AUTOSAR XML (schema 00048)
package /MICROSAR/ComM_swc
  mode declaration group ComMMode: initial-mode=COMM_NO_COMMUNICATION
    mode COMM_NO_COMMUNICATION
    mode COMM_SILENT_COMMUNICATION
    mode COMM_FULL_COMMUNICATION
  data type mapping set ComMMode_DataTypeMappingSet: mode-request-type-map{implementation-data-type=ComM_ModeType, mode-group=ComMMode}  # Data Mapping for the Mode Declaration Group ComMMode.
package /MICROSAR/ComM_swc/DataTypes
  4 x impl type, all with category=TYPE_REFERENCE:
    ComM_ModeType: compu {0=COMM_NO_COMMUNICATION, 1=COMM_SILENT_COMMUNICATION, 2=COMM_FULL_COMMUNICATION}, range raw 0..3, implementation-data-type=uint8
    ComM_InhibitionStatusType: range raw 0..255, implementation-data-type=uint8
    ComM_UserHandleType: range raw 0..65535, implementation-data-type=uint16
    NetworkHandleType: range raw 0..255, implementation-data-type=uint8, type-emitter=ComM
package /MICROSAR/ComM_swc/Interfaces
  4 x client server interface, all with is-service=true, service-kind=COM-MANAGER:
    ComM_UserRequest
      5 x operation:
        RequestComMode: possible-error=[ComM_UserRequest/E_NOT_OK, E_MODE_LIMITATION]
          arg ComMode: type=ComM_ModeType, direction=IN
        GetCurrentComMode: possible-error=ComM_UserRequest/E_NOT_OK
          arg ComMode: type=ComM_ModeType, direction=OUT
        GetMaxComMode: possible-error=ComM_UserRequest/E_NOT_OK
          arg ComMode: type=ComM_ModeType, direction=OUT
        GetRequestedComMode: possible-error=ComM_UserRequest/E_NOT_OK
          arg ComMode: type=ComM_ModeType, direction=OUT
        GetCurrentPNCComMode: possible-error=[ComM_UserRequest/E_NOT_OK, E_MULTIPLE_PNC_ASSIGNED, E_NO_PNC_ASSIGNED]
          arg ComMode: type=ComM_ModeType, direction=OUT
      4 x error:
        E_NOT_OK: error-code=1
        E_MODE_LIMITATION: error-code=2
        E_MULTIPLE_PNC_ASSIGNED: error-code=3
        E_NO_PNC_ASSIGNED: error-code=4
    ComM_ECUModeLimitation
      4 x operation, all with possible-error=ComM_ECUModeLimitation/E_NOT_OK:
        LimitECUToNoComMode
          arg Status: type=boolean, direction=IN
        ReadInhibitCounter
          arg CounterValue: type=uint16, direction=OUT
        ResetInhibitCounter
        SetECUGroupClassification
          arg Status: type=ComM_InhibitionStatusType, direction=IN
      error E_NOT_OK: error-code=1
    ComM_ChannelWakeUp
      operation PreventWakeUp: possible-error=ComM_ChannelWakeUp/E_NOT_OK
        arg Status: type=boolean, direction=IN
      operation GetInhibitionStatus: possible-error=ComM_ChannelWakeUp/E_NOT_OK
        arg Status: type=ComM_InhibitionStatusType, direction=OUT
      error E_NOT_OK: error-code=1
    ComM_ChannelLimitation
      operation LimitChannelToNoComMode: possible-error=ComM_ChannelLimitation/E_NOT_OK
        arg Status: type=boolean, direction=IN
      operation GetInhibitionStatus: possible-error=ComM_ChannelLimitation/E_NOT_OK
        arg Status: type=ComM_InhibitionStatusType, direction=OUT
      error E_NOT_OK: error-code=1
  mode switch interface ComM_CurrentMode: is-service=true, service-kind=COM-MANAGER
    mode group currentMode: type=ComMMode
package /MICROSAR/ComM_swc/ComponentTypes
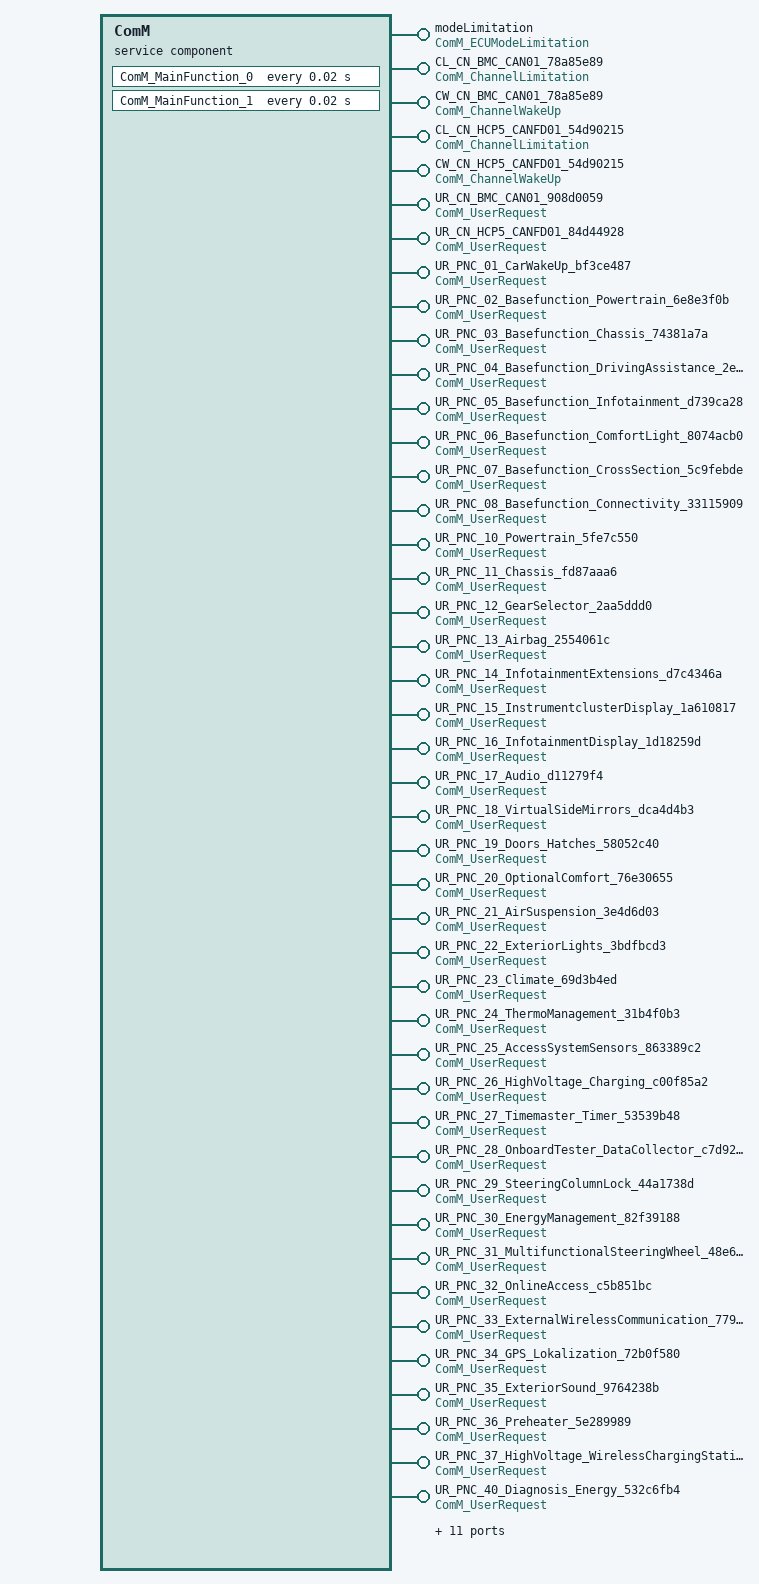
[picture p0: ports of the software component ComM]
  service sw component type ComM: category=SERVICE_COMPONENT
    55 x provide port:
      modeLimitation: provided-interface=ComM_ECUModeLimitation
      CL_CN_BMC_CAN01_78a85e89: provided-interface=ComM_ChannelLimitation
      CW_CN_BMC_CAN01_78a85e89: provided-interface=ComM_ChannelWakeUp
      CL_CN_HCP5_CANFD01_54d90215: provided-interface=ComM_ChannelLimitation
      CW_CN_HCP5_CANFD01_54d90215: provided-interface=ComM_ChannelWakeUp
      UR_CN_BMC_CAN01_908d0059: provided-interface=ComM_UserRequest
      UR_CN_HCP5_CANFD01_84d44928: provided-interface=ComM_UserRequest
      UR_PNC_01_CarWakeUp_bf3ce487: provided-interface=ComM_UserRequest
      UR_PNC_02_Basefunction_Powertrain_6e8e3f0b: provided-interface=ComM_UserRequest
      UR_PNC_03_Basefunction_Chassis_74381a7a: provided-interface=ComM_UserRequest
      UR_PNC_04_Basefunction_DrivingAssistance_2e755e80: provided-interface=ComM_UserRequest
      UR_PNC_05_Basefunction_Infotainment_d739ca28: provided-interface=ComM_UserRequest
      UR_PNC_06_Basefunction_ComfortLight_8074acb0: provided-interface=ComM_UserRequest
      UR_PNC_07_Basefunction_CrossSection_5c9febde: provided-interface=ComM_UserRequest
      UR_PNC_08_Basefunction_Connectivity_33115909: provided-interface=ComM_UserRequest
      UR_PNC_10_Powertrain_5fe7c550: provided-interface=ComM_UserRequest
      UR_PNC_11_Chassis_fd87aaa6: provided-interface=ComM_UserRequest
      UR_PNC_12_GearSelector_2aa5ddd0: provided-interface=ComM_UserRequest
      UR_PNC_13_Airbag_2554061c: provided-interface=ComM_UserRequest
      UR_PNC_14_InfotainmentExtensions_d7c4346a: provided-interface=ComM_UserRequest
      UR_PNC_15_InstrumentclusterDisplay_1a610817: provided-interface=ComM_UserRequest
      UR_PNC_16_InfotainmentDisplay_1d18259d: provided-interface=ComM_UserRequest
      UR_PNC_17_Audio_d11279f4: provided-interface=ComM_UserRequest
      UR_PNC_18_VirtualSideMirrors_dca4d4b3: provided-interface=ComM_UserRequest
      UR_PNC_19_Doors_Hatches_58052c40: provided-interface=ComM_UserRequest
      UR_PNC_20_OptionalComfort_76e30655: provided-interface=ComM_UserRequest
      UR_PNC_21_AirSuspension_3e4d6d03: provided-interface=ComM_UserRequest
      UR_PNC_22_ExteriorLights_3bdfbcd3: provided-interface=ComM_UserRequest
      UR_PNC_23_Climate_69d3b4ed: provided-interface=ComM_UserRequest
      UR_PNC_24_ThermoManagement_31b4f0b3: provided-interface=ComM_UserRequest
      UR_PNC_25_AccessSystemSensors_863389c2: provided-interface=ComM_UserRequest
      UR_PNC_26_HighVoltage_Charging_c00f85a2: provided-interface=ComM_UserRequest
      UR_PNC_27_Timemaster_Timer_53539b48: provided-interface=ComM_UserRequest
      UR_PNC_28_OnboardTester_DataCollector_c7d92e04: provided-interface=ComM_UserRequest
      UR_PNC_29_SteeringColumnLock_44a1738d: provided-interface=ComM_UserRequest
      UR_PNC_30_EnergyManagement_82f39188: provided-interface=ComM_UserRequest
      UR_PNC_31_MultifunctionalSteeringWheel_48e6d667: provided-interface=ComM_UserRequest
      UR_PNC_32_OnlineAccess_c5b851bc: provided-interface=ComM_UserRequest
      UR_PNC_33_ExternalWirelessCommunication_779a8708: provided-interface=ComM_UserRequest
      UR_PNC_34_GPS_Lokalization_72b0f580: provided-interface=ComM_UserRequest
      UR_PNC_35_ExteriorSound_9764238b: provided-interface=ComM_UserRequest
      UR_PNC_36_Preheater_5e289989: provided-interface=ComM_UserRequest
      UR_PNC_37_HighVoltage_WirelessChargingStation_f111c76f: provided-interface=ComM_UserRequest
      UR_PNC_40_Diagnosis_Energy_532c6fb4: provided-interface=ComM_UserRequest
      UR_PNC_41_Diagnosis_Powertrain_0ac6ac8b: provided-interface=ComM_UserRequest
      UR_PNC_42_Diagnosis_FlexRay_f6dcf44d: provided-interface=ComM_UserRequest
      UR_PNC_43_Diagnosis_DrivingAssistance_84f09039: provided-interface=ComM_UserRequest
      UR_PNC_44_Diagnosis_Infotainment_3909218a: provided-interface=ComM_UserRequest
      UR_PNC_45_Diagnosis_Comfort_7eea372a: provided-interface=ComM_UserRequest
      UR_PNC_46_Diagnosis_Light_5140c135: provided-interface=ComM_UserRequest
      UR_PNC_47_Diagnosis_ComfortLINs_70cf0372: provided-interface=ComM_UserRequest
      UR_PNC_48_Diagnosis_ClimateTmeLINs_b4c40b49: provided-interface=ComM_UserRequest
      UR_PNC_53_Lock_Unlock_bfb0b2ca: provided-interface=ComM_UserRequest
      UR_PNC_55_Dimming_4909a14c: provided-interface=ComM_UserRequest
      UR_PNC_56_Charging_Status_cad5dfb4: provided-interface=ComM_UserRequest
    behavior ComMInternalBehavior: data-type-mapping=ComMMode_DataTypeMappingSet, handle-termination-and-restart=NO-SUPPORT, included-data-type-set=data-type=[ComM_ModeType, ComM_InhibitionStatusType, ComM_UserHandleType, NetworkHandleType]
      timing event Timer_ComM_MainFunction_0: start-on-event=ComM_MainFunction_0, period=0.02
      timing event Timer_ComM_MainFunction_1: start-on-event=ComM_MainFunction_1, period=0.02
      262 x operation invoked event:
        OpEventLimitECUToNoComMode_LimitECUToNoComMode_modeLimitation: start-on-event=LimitECUToNoComMode, operation=modeLimitation.LimitECUToNoComMode
        OpEventReadInhibitCounter_ReadInhibitCounter_modeLimitation: start-on-event=ReadInhibitCounter, operation=modeLimitation.ReadInhibitCounter
        OpEventResetInhibitCounter_ResetInhibitCounter_modeLimitation: start-on-event=ResetInhibitCounter, operation=modeLimitation.ResetInhibitCounter
        OpEventSetECUGroupClassification_SetECUGroupClassification_modeLimitation: start-on-event=SetECUGroupClassification, operation=modeLimitation.SetECUGroupClassification
        OpEventGetInhibitionStatus_GetInhibitionStatus_CL_CN_BMC_CAN01_78a85e89: start-on-event=GetInhibitionStatus, operation=CL_CN_BMC_CAN01_78a85e89.GetInhibitionStatus
        OpEventGetInhibitionStatus_GetInhibitionStatus_CW_CN_BMC_CAN01_78a85e89: start-on-event=GetInhibitionStatus, operation=CW_CN_BMC_CAN01_78a85e89.GetInhibitionStatus
        OpEventGetInhibitionStatus_GetInhibitionStatus_CL_CN_HCP5_CANFD01_54d90215: start-on-event=GetInhibitionStatus, operation=CL_CN_HCP5_CANFD01_54d90215.GetInhibitionStatus
        OpEventGetInhibitionStatus_GetInhibitionStatus_CW_CN_HCP5_CANFD01_54d90215: start-on-event=GetInhibitionStatus, operation=CW_CN_HCP5_CANFD01_54d90215.GetInhibitionStatus
        OpEventLimitChannelToNoComMode_LimitChannelToNoComMode_CL_CN_BMC_CAN01_78a85e89: start-on-event=LimitChannelToNoComMode, operation=CL_CN_BMC_CAN01_78a85e89.LimitChannelToNoComMode
        OpEventLimitChannelToNoComMode_LimitChannelToNoComMode_CL_CN_HCP5_CANFD01_54d90215: start-on-event=LimitChannelToNoComMode, operation=CL_CN_HCP5_CANFD01_54d90215.LimitChannelToNoComMode
        OpEventPreventWakeUp_PreventWakeUp_CW_CN_BMC_CAN01_78a85e89: start-on-event=PreventWakeUp, operation=CW_CN_BMC_CAN01_78a85e89.PreventWakeUp
        OpEventPreventWakeUp_PreventWakeUp_CW_CN_HCP5_CANFD01_54d90215: start-on-event=PreventWakeUp, operation=CW_CN_HCP5_CANFD01_54d90215.PreventWakeUp
        OpEventRequestComMode_RequestComMode_UR_CN_BMC_CAN01_908d0059: start-on-event=RequestComMode, operation=UR_CN_BMC_CAN01_908d0059.RequestComMode
        OpEventRequestComMode_RequestComMode_UR_CN_HCP5_CANFD01_84d44928: start-on-event=RequestComMode, operation=UR_CN_HCP5_CANFD01_84d44928.RequestComMode
        OpEventRequestComMode_RequestComMode_UR_PNC_01_CarWakeUp_bf3ce487: start-on-event=RequestComMode, operation=UR_PNC_01_CarWakeUp_bf3ce487.RequestComMode
        OpEventRequestComMode_RequestComMode_UR_PNC_02_Basefunction_Powertrain_6e8e3f0b: start-on-event=RequestComMode, operation=UR_PNC_02_Basefunction_Powertrain_6e8e3f0b.RequestComMode
        OpEventRequestComMode_RequestComMode_UR_PNC_03_Basefunction_Chassis_74381a7a: start-on-event=RequestComMode, operation=UR_PNC_03_Basefunction_Chassis_74381a7a.RequestComMode
        OpEventRequestComMode_RequestComMode_UR_PNC_04_Basefunction_DrivingAssistance_2e755e80: start-on-event=RequestComMode, operation=UR_PNC_04_Basefunction_DrivingAssistance_2e755e80.RequestComMode
        OpEventRequestComMode_RequestComMode_UR_PNC_05_Basefunction_Infotainment_d739ca28: start-on-event=RequestComMode, operation=UR_PNC_05_Basefunction_Infotainment_d739ca28.RequestComMode
        OpEventRequestComMode_RequestComMode_UR_PNC_06_Basefunction_ComfortLight_8074acb0: start-on-event=RequestComMode, operation=UR_PNC_06_Basefunction_ComfortLight_8074acb0.RequestComMode
        OpEventRequestComMode_RequestComMode_UR_PNC_07_Basefunction_CrossSection_5c9febde: start-on-event=RequestComMode, operation=UR_PNC_07_Basefunction_CrossSection_5c9febde.RequestComMode
        OpEventRequestComMode_RequestComMode_UR_PNC_08_Basefunction_Connectivity_33115909: start-on-event=RequestComMode, operation=UR_PNC_08_Basefunction_Connectivity_33115909.RequestComMode
        OpEventRequestComMode_RequestComMode_UR_PNC_10_Powertrain_5fe7c550: start-on-event=RequestComMode, operation=UR_PNC_10_Powertrain_5fe7c550.RequestComMode
        OpEventRequestComMode_RequestComMode_UR_PNC_11_Chassis_fd87aaa6: start-on-event=RequestComMode, operation=UR_PNC_11_Chassis_fd87aaa6.RequestComMode
        OpEventRequestComMode_RequestComMode_UR_PNC_12_GearSelector_2aa5ddd0: start-on-event=RequestComMode, operation=UR_PNC_12_GearSelector_2aa5ddd0.RequestComMode
        OpEventRequestComMode_RequestComMode_UR_PNC_13_Airbag_2554061c: start-on-event=RequestComMode, operation=UR_PNC_13_Airbag_2554061c.RequestComMode
        OpEventRequestComMode_RequestComMode_UR_PNC_14_InfotainmentExtensions_d7c4346a: start-on-event=RequestComMode, operation=UR_PNC_14_InfotainmentExtensions_d7c4346a.RequestComMode
        OpEventRequestComMode_RequestComMode_UR_PNC_15_InstrumentclusterDisplay_1a610817: start-on-event=RequestComMode, operation=UR_PNC_15_InstrumentclusterDisplay_1a610817.RequestComMode
        OpEventRequestComMode_RequestComMode_UR_PNC_16_InfotainmentDisplay_1d18259d: start-on-event=RequestComMode, operation=UR_PNC_16_InfotainmentDisplay_1d18259d.RequestComMode
        OpEventRequestComMode_RequestComMode_UR_PNC_17_Audio_d11279f4: start-on-event=RequestComMode, operation=UR_PNC_17_Audio_d11279f4.RequestComMode
        OpEventRequestComMode_RequestComMode_UR_PNC_18_VirtualSideMirrors_dca4d4b3: start-on-event=RequestComMode, operation=UR_PNC_18_VirtualSideMirrors_dca4d4b3.RequestComMode
        OpEventRequestComMode_RequestComMode_UR_PNC_19_Doors_Hatches_58052c40: start-on-event=RequestComMode, operation=UR_PNC_19_Doors_Hatches_58052c40.RequestComMode
        OpEventRequestComMode_RequestComMode_UR_PNC_20_OptionalComfort_76e30655: start-on-event=RequestComMode, operation=UR_PNC_20_OptionalComfort_76e30655.RequestComMode
        OpEventRequestComMode_RequestComMode_UR_PNC_21_AirSuspension_3e4d6d03: start-on-event=RequestComMode, operation=UR_PNC_21_AirSuspension_3e4d6d03.RequestComMode
        OpEventRequestComMode_RequestComMode_UR_PNC_22_ExteriorLights_3bdfbcd3: start-on-event=RequestComMode, operation=UR_PNC_22_ExteriorLights_3bdfbcd3.RequestComMode
        OpEventRequestComMode_RequestComMode_UR_PNC_23_Climate_69d3b4ed: start-on-event=RequestComMode, operation=UR_PNC_23_Climate_69d3b4ed.RequestComMode
        OpEventRequestComMode_RequestComMode_UR_PNC_24_ThermoManagement_31b4f0b3: start-on-event=RequestComMode, operation=UR_PNC_24_ThermoManagement_31b4f0b3.RequestComMode
        OpEventRequestComMode_RequestComMode_UR_PNC_25_AccessSystemSensors_863389c2: start-on-event=RequestComMode, operation=UR_PNC_25_AccessSystemSensors_863389c2.RequestComMode
        OpEventRequestComMode_RequestComMode_UR_PNC_26_HighVoltage_Charging_c00f85a2: start-on-event=RequestComMode, operation=UR_PNC_26_HighVoltage_Charging_c00f85a2.RequestComMode
        OpEventRequestComMode_RequestComMode_UR_PNC_27_Timemaster_Timer_53539b48: start-on-event=RequestComMode, operation=UR_PNC_27_Timemaster_Timer_53539b48.RequestComMode
        OpEventRequestComMode_RequestComMode_UR_PNC_28_OnboardTester_DataCollector_c7d92e04: start-on-event=RequestComMode, operation=UR_PNC_28_OnboardTester_DataCollector_c7d92e04.RequestComMode
        OpEventRequestComMode_RequestComMode_UR_PNC_29_SteeringColumnLock_44a1738d: start-on-event=RequestComMode, operation=UR_PNC_29_SteeringColumnLock_44a1738d.RequestComMode
        OpEventRequestComMode_RequestComMode_UR_PNC_30_EnergyManagement_82f39188: start-on-event=RequestComMode, operation=UR_PNC_30_EnergyManagement_82f39188.RequestComMode
        OpEventRequestComMode_RequestComMode_UR_PNC_31_MultifunctionalSteeringWheel_48e6d667: start-on-event=RequestComMode, operation=UR_PNC_31_MultifunctionalSteeringWheel_48e6d667.RequestComMode
        OpEventRequestComMode_RequestComMode_UR_PNC_32_OnlineAccess_c5b851bc: start-on-event=RequestComMode, operation=UR_PNC_32_OnlineAccess_c5b851bc.RequestComMode
        OpEventRequestComMode_RequestComMode_UR_PNC_33_ExternalWirelessCommunication_779a8708: start-on-event=RequestComMode, operation=UR_PNC_33_ExternalWirelessCommunication_779a8708.RequestComMode
        OpEventRequestComMode_RequestComMode_UR_PNC_34_GPS_Lokalization_72b0f580: start-on-event=RequestComMode, operation=UR_PNC_34_GPS_Lokalization_72b0f580.RequestComMode
        OpEventRequestComMode_RequestComMode_UR_PNC_35_ExteriorSound_9764238b: start-on-event=RequestComMode, operation=UR_PNC_35_ExteriorSound_9764238b.RequestComMode
        OpEventRequestComMode_RequestComMode_UR_PNC_36_Preheater_5e289989: start-on-event=RequestComMode, operation=UR_PNC_36_Preheater_5e289989.RequestComMode
        OpEventRequestComMode_RequestComMode_UR_PNC_37_HighVoltage_WirelessChargingStation_f111c76f: start-on-event=RequestComMode, operation=UR_PNC_37_HighVoltage_WirelessChargingStation_f111c76f.RequestComMode
        OpEventRequestComMode_RequestComMode_UR_PNC_40_Diagnosis_Energy_532c6fb4: start-on-event=RequestComMode, operation=UR_PNC_40_Diagnosis_Energy_532c6fb4.RequestComMode
        OpEventRequestComMode_RequestComMode_UR_PNC_41_Diagnosis_Powertrain_0ac6ac8b: start-on-event=RequestComMode, operation=UR_PNC_41_Diagnosis_Powertrain_0ac6ac8b.RequestComMode
        OpEventRequestComMode_RequestComMode_UR_PNC_42_Diagnosis_FlexRay_f6dcf44d: start-on-event=RequestComMode, operation=UR_PNC_42_Diagnosis_FlexRay_f6dcf44d.RequestComMode
        OpEventRequestComMode_RequestComMode_UR_PNC_43_Diagnosis_DrivingAssistance_84f09039: start-on-event=RequestComMode, operation=UR_PNC_43_Diagnosis_DrivingAssistance_84f09039.RequestComMode
        OpEventRequestComMode_RequestComMode_UR_PNC_44_Diagnosis_Infotainment_3909218a: start-on-event=RequestComMode, operation=UR_PNC_44_Diagnosis_Infotainment_3909218a.RequestComMode
        OpEventRequestComMode_RequestComMode_UR_PNC_45_Diagnosis_Comfort_7eea372a: start-on-event=RequestComMode, operation=UR_PNC_45_Diagnosis_Comfort_7eea372a.RequestComMode
        OpEventRequestComMode_RequestComMode_UR_PNC_46_Diagnosis_Light_5140c135: start-on-event=RequestComMode, operation=UR_PNC_46_Diagnosis_Light_5140c135.RequestComMode
        OpEventRequestComMode_RequestComMode_UR_PNC_47_Diagnosis_ComfortLINs_70cf0372: start-on-event=RequestComMode, operation=UR_PNC_47_Diagnosis_ComfortLINs_70cf0372.RequestComMode
        OpEventRequestComMode_RequestComMode_UR_PNC_48_Diagnosis_ClimateTmeLINs_b4c40b49: start-on-event=RequestComMode, operation=UR_PNC_48_Diagnosis_ClimateTmeLINs_b4c40b49.RequestComMode
        OpEventRequestComMode_RequestComMode_UR_PNC_53_Lock_Unlock_bfb0b2ca: start-on-event=RequestComMode, operation=UR_PNC_53_Lock_Unlock_bfb0b2ca.RequestComMode
        OpEventRequestComMode_RequestComMode_UR_PNC_55_Dimming_4909a14c: start-on-event=RequestComMode, operation=UR_PNC_55_Dimming_4909a14c.RequestComMode
        OpEventRequestComMode_RequestComMode_UR_PNC_56_Charging_Status_cad5dfb4: start-on-event=RequestComMode, operation=UR_PNC_56_Charging_Status_cad5dfb4.RequestComMode
        OpEventGetCurrentComMode_GetCurrentComMode_UR_CN_BMC_CAN01_908d0059: start-on-event=GetCurrentComMode, operation=UR_CN_BMC_CAN01_908d0059.GetCurrentComMode
        OpEventGetCurrentComMode_GetCurrentComMode_UR_CN_HCP5_CANFD01_84d44928: start-on-event=GetCurrentComMode, operation=UR_CN_HCP5_CANFD01_84d44928.GetCurrentComMode
        OpEventGetCurrentComMode_GetCurrentComMode_UR_PNC_01_CarWakeUp_bf3ce487: start-on-event=GetCurrentComMode, operation=UR_PNC_01_CarWakeUp_bf3ce487.GetCurrentComMode
        OpEventGetCurrentComMode_GetCurrentComMode_UR_PNC_02_Basefunction_Powertrain_6e8e3f0b: start-on-event=GetCurrentComMode, operation=UR_PNC_02_Basefunction_Powertrain_6e8e3f0b.GetCurrentComMode
        OpEventGetCurrentComMode_GetCurrentComMode_UR_PNC_03_Basefunction_Chassis_74381a7a: start-on-event=GetCurrentComMode, operation=UR_PNC_03_Basefunction_Chassis_74381a7a.GetCurrentComMode
        OpEventGetCurrentComMode_GetCurrentComMode_UR_PNC_04_Basefunction_DrivingAssistance_2e755e80: start-on-event=GetCurrentComMode, operation=UR_PNC_04_Basefunction_DrivingAssistance_2e755e80.GetCurrentComMode
        OpEventGetCurrentComMode_GetCurrentComMode_UR_PNC_05_Basefunction_Infotainment_d739ca28: start-on-event=GetCurrentComMode, operation=UR_PNC_05_Basefunction_Infotainment_d739ca28.GetCurrentComMode
        OpEventGetCurrentComMode_GetCurrentComMode_UR_PNC_06_Basefunction_ComfortLight_8074acb0: start-on-event=GetCurrentComMode, operation=UR_PNC_06_Basefunction_ComfortLight_8074acb0.GetCurrentComMode
        OpEventGetCurrentComMode_GetCurrentComMode_UR_PNC_07_Basefunction_CrossSection_5c9febde: start-on-event=GetCurrentComMode, operation=UR_PNC_07_Basefunction_CrossSection_5c9febde.GetCurrentComMode
        OpEventGetCurrentComMode_GetCurrentComMode_UR_PNC_08_Basefunction_Connectivity_33115909: start-on-event=GetCurrentComMode, operation=UR_PNC_08_Basefunction_Connectivity_33115909.GetCurrentComMode
        OpEventGetCurrentComMode_GetCurrentComMode_UR_PNC_10_Powertrain_5fe7c550: start-on-event=GetCurrentComMode, operation=UR_PNC_10_Powertrain_5fe7c550.GetCurrentComMode
        OpEventGetCurrentComMode_GetCurrentComMode_UR_PNC_11_Chassis_fd87aaa6: start-on-event=GetCurrentComMode, operation=UR_PNC_11_Chassis_fd87aaa6.GetCurrentComMode
        OpEventGetCurrentComMode_GetCurrentComMode_UR_PNC_12_GearSelector_2aa5ddd0: start-on-event=GetCurrentComMode, operation=UR_PNC_12_GearSelector_2aa5ddd0.GetCurrentComMode
        OpEventGetCurrentComMode_GetCurrentComMode_UR_PNC_13_Airbag_2554061c: start-on-event=GetCurrentComMode, operation=UR_PNC_13_Airbag_2554061c.GetCurrentComMode
        OpEventGetCurrentComMode_GetCurrentComMode_UR_PNC_14_InfotainmentExtensions_d7c4346a: start-on-event=GetCurrentComMode, operation=UR_PNC_14_InfotainmentExtensions_d7c4346a.GetCurrentComMode
        OpEventGetCurrentComMode_GetCurrentComMode_UR_PNC_15_InstrumentclusterDisplay_1a610817: start-on-event=GetCurrentComMode, operation=UR_PNC_15_InstrumentclusterDisplay_1a610817.GetCurrentComMode
        OpEventGetCurrentComMode_GetCurrentComMode_UR_PNC_16_InfotainmentDisplay_1d18259d: start-on-event=GetCurrentComMode, operation=UR_PNC_16_InfotainmentDisplay_1d18259d.GetCurrentComMode
        OpEventGetCurrentComMode_GetCurrentComMode_UR_PNC_17_Audio_d11279f4: start-on-event=GetCurrentComMode, operation=UR_PNC_17_Audio_d11279f4.GetCurrentComMode
        OpEventGetCurrentComMode_GetCurrentComMode_UR_PNC_18_VirtualSideMirrors_dca4d4b3: start-on-event=GetCurrentComMode, operation=UR_PNC_18_VirtualSideMirrors_dca4d4b3.GetCurrentComMode
        OpEventGetCurrentComMode_GetCurrentComMode_UR_PNC_19_Doors_Hatches_58052c40: start-on-event=GetCurrentComMode, operation=UR_PNC_19_Doors_Hatches_58052c40.GetCurrentComMode
        OpEventGetCurrentComMode_GetCurrentComMode_UR_PNC_20_OptionalComfort_76e30655: start-on-event=GetCurrentComMode, operation=UR_PNC_20_OptionalComfort_76e30655.GetCurrentComMode
        OpEventGetCurrentComMode_GetCurrentComMode_UR_PNC_21_AirSuspension_3e4d6d03: start-on-event=GetCurrentComMode, operation=UR_PNC_21_AirSuspension_3e4d6d03.GetCurrentComMode
        OpEventGetCurrentComMode_GetCurrentComMode_UR_PNC_22_ExteriorLights_3bdfbcd3: start-on-event=GetCurrentComMode, operation=UR_PNC_22_ExteriorLights_3bdfbcd3.GetCurrentComMode
        OpEventGetCurrentComMode_GetCurrentComMode_UR_PNC_23_Climate_69d3b4ed: start-on-event=GetCurrentComMode, operation=UR_PNC_23_Climate_69d3b4ed.GetCurrentComMode
        OpEventGetCurrentComMode_GetCurrentComMode_UR_PNC_24_ThermoManagement_31b4f0b3: start-on-event=GetCurrentComMode, operation=UR_PNC_24_ThermoManagement_31b4f0b3.GetCurrentComMode
        OpEventGetCurrentComMode_GetCurrentComMode_UR_PNC_25_AccessSystemSensors_863389c2: start-on-event=GetCurrentComMode, operation=UR_PNC_25_AccessSystemSensors_863389c2.GetCurrentComMode
        OpEventGetCurrentComMode_GetCurrentComMode_UR_PNC_26_HighVoltage_Charging_c00f85a2: start-on-event=GetCurrentComMode, operation=UR_PNC_26_HighVoltage_Charging_c00f85a2.GetCurrentComMode
        OpEventGetCurrentComMode_GetCurrentComMode_UR_PNC_27_Timemaster_Timer_53539b48: start-on-event=GetCurrentComMode, operation=UR_PNC_27_Timemaster_Timer_53539b48.GetCurrentComMode
        OpEventGetCurrentComMode_GetCurrentComMode_UR_PNC_28_OnboardTester_DataCollector_c7d92e04: start-on-event=GetCurrentComMode, operation=UR_PNC_28_OnboardTester_DataCollector_c7d92e04.GetCurrentComMode
        OpEventGetCurrentComMode_GetCurrentComMode_UR_PNC_29_SteeringColumnLock_44a1738d: start-on-event=GetCurrentComMode, operation=UR_PNC_29_SteeringColumnLock_44a1738d.GetCurrentComMode
        OpEventGetCurrentComMode_GetCurrentComMode_UR_PNC_30_EnergyManagement_82f39188: start-on-event=GetCurrentComMode, operation=UR_PNC_30_EnergyManagement_82f39188.GetCurrentComMode
        OpEventGetCurrentComMode_GetCurrentComMode_UR_PNC_31_MultifunctionalSteeringWheel_48e6d667: start-on-event=GetCurrentComMode, operation=UR_PNC_31_MultifunctionalSteeringWheel_48e6d667.GetCurrentComMode
        OpEventGetCurrentComMode_GetCurrentComMode_UR_PNC_32_OnlineAccess_c5b851bc: start-on-event=GetCurrentComMode, operation=UR_PNC_32_OnlineAccess_c5b851bc.GetCurrentComMode
        OpEventGetCurrentComMode_GetCurrentComMode_UR_PNC_33_ExternalWirelessCommunication_779a8708: start-on-event=GetCurrentComMode, operation=UR_PNC_33_ExternalWirelessCommunication_779a8708.GetCurrentComMode
        OpEventGetCurrentComMode_GetCurrentComMode_UR_PNC_34_GPS_Lokalization_72b0f580: start-on-event=GetCurrentComMode, operation=UR_PNC_34_GPS_Lokalization_72b0f580.GetCurrentComMode
        OpEventGetCurrentComMode_GetCurrentComMode_UR_PNC_35_ExteriorSound_9764238b: start-on-event=GetCurrentComMode, operation=UR_PNC_35_ExteriorSound_9764238b.GetCurrentComMode
        OpEventGetCurrentComMode_GetCurrentComMode_UR_PNC_36_Preheater_5e289989: start-on-event=GetCurrentComMode, operation=UR_PNC_36_Preheater_5e289989.GetCurrentComMode
        OpEventGetCurrentComMode_GetCurrentComMode_UR_PNC_37_HighVoltage_WirelessChargingStation_f111c76f: start-on-event=GetCurrentComMode, operation=UR_PNC_37_HighVoltage_WirelessChargingStation_f111c76f.GetCurrentComMode
        OpEventGetCurrentComMode_GetCurrentComMode_UR_PNC_40_Diagnosis_Energy_532c6fb4: start-on-event=GetCurrentComMode, operation=UR_PNC_40_Diagnosis_Energy_532c6fb4.GetCurrentComMode
        OpEventGetCurrentComMode_GetCurrentComMode_UR_PNC_41_Diagnosis_Powertrain_0ac6ac8b: start-on-event=GetCurrentComMode, operation=UR_PNC_41_Diagnosis_Powertrain_0ac6ac8b.GetCurrentComMode
        OpEventGetCurrentComMode_GetCurrentComMode_UR_PNC_42_Diagnosis_FlexRay_f6dcf44d: start-on-event=GetCurrentComMode, operation=UR_PNC_42_Diagnosis_FlexRay_f6dcf44d.GetCurrentComMode
        OpEventGetCurrentComMode_GetCurrentComMode_UR_PNC_43_Diagnosis_DrivingAssistance_84f09039: start-on-event=GetCurrentComMode, operation=UR_PNC_43_Diagnosis_DrivingAssistance_84f09039.GetCurrentComMode
        OpEventGetCurrentComMode_GetCurrentComMode_UR_PNC_44_Diagnosis_Infotainment_3909218a: start-on-event=GetCurrentComMode, operation=UR_PNC_44_Diagnosis_Infotainment_3909218a.GetCurrentComMode
        OpEventGetCurrentComMode_GetCurrentComMode_UR_PNC_45_Diagnosis_Comfort_7eea372a: start-on-event=GetCurrentComMode, operation=UR_PNC_45_Diagnosis_Comfort_7eea372a.GetCurrentComMode
        OpEventGetCurrentComMode_GetCurrentComMode_UR_PNC_46_Diagnosis_Light_5140c135: start-on-event=GetCurrentComMode, operation=UR_PNC_46_Diagnosis_Light_5140c135.GetCurrentComMode
        OpEventGetCurrentComMode_GetCurrentComMode_UR_PNC_47_Diagnosis_ComfortLINs_70cf0372: start-on-event=GetCurrentComMode, operation=UR_PNC_47_Diagnosis_ComfortLINs_70cf0372.GetCurrentComMode
        OpEventGetCurrentComMode_GetCurrentComMode_UR_PNC_48_Diagnosis_ClimateTmeLINs_b4c40b49: start-on-event=GetCurrentComMode, operation=UR_PNC_48_Diagnosis_ClimateTmeLINs_b4c40b49.GetCurrentComMode
        OpEventGetCurrentComMode_GetCurrentComMode_UR_PNC_53_Lock_Unlock_bfb0b2ca: start-on-event=GetCurrentComMode, operation=UR_PNC_53_Lock_Unlock_bfb0b2ca.GetCurrentComMode
        OpEventGetCurrentComMode_GetCurrentComMode_UR_PNC_55_Dimming_4909a14c: start-on-event=GetCurrentComMode, operation=UR_PNC_55_Dimming_4909a14c.GetCurrentComMode
        OpEventGetCurrentComMode_GetCurrentComMode_UR_PNC_56_Charging_Status_cad5dfb4: start-on-event=GetCurrentComMode, operation=UR_PNC_56_Charging_Status_cad5dfb4.GetCurrentComMode
        OpEventGetCurrentPNCComMode_GetCurrentPNCComMode_UR_CN_BMC_CAN01_908d0059: start-on-event=GetCurrentPNCComMode, operation=UR_CN_BMC_CAN01_908d0059.GetCurrentPNCComMode
        OpEventGetCurrentPNCComMode_GetCurrentPNCComMode_UR_CN_HCP5_CANFD01_84d44928: start-on-event=GetCurrentPNCComMode, operation=UR_CN_HCP5_CANFD01_84d44928.GetCurrentPNCComMode
        OpEventGetCurrentPNCComMode_GetCurrentPNCComMode_UR_PNC_01_CarWakeUp_bf3ce487: start-on-event=GetCurrentPNCComMode, operation=UR_PNC_01_CarWakeUp_bf3ce487.GetCurrentPNCComMode
        OpEventGetCurrentPNCComMode_GetCurrentPNCComMode_UR_PNC_02_Basefunction_Powertrain_6e8e3f0b: start-on-event=GetCurrentPNCComMode, operation=UR_PNC_02_Basefunction_Powertrain_6e8e3f0b.GetCurrentPNCComMode
        OpEventGetCurrentPNCComMode_GetCurrentPNCComMode_UR_PNC_03_Basefunction_Chassis_74381a7a: start-on-event=GetCurrentPNCComMode, operation=UR_PNC_03_Basefunction_Chassis_74381a7a.GetCurrentPNCComMode
        OpEventGetCurrentPNCComMode_GetCurrentPNCComMode_UR_PNC_04_Basefunction_DrivingAssistance_2e755e80: start-on-event=GetCurrentPNCComMode, operation=UR_PNC_04_Basefunction_DrivingAssistance_2e755e80.GetCurrentPNCComMode
        OpEventGetCurrentPNCComMode_GetCurrentPNCComMode_UR_PNC_05_Basefunction_Infotainment_d739ca28: start-on-event=GetCurrentPNCComMode, operation=UR_PNC_05_Basefunction_Infotainment_d739ca28.GetCurrentPNCComMode
        OpEventGetCurrentPNCComMode_GetCurrentPNCComMode_UR_PNC_06_Basefunction_ComfortLight_8074acb0: start-on-event=GetCurrentPNCComMode, operation=UR_PNC_06_Basefunction_ComfortLight_8074acb0.GetCurrentPNCComMode
        OpEventGetCurrentPNCComMode_GetCurrentPNCComMode_UR_PNC_07_Basefunction_CrossSection_5c9febde: start-on-event=GetCurrentPNCComMode, operation=UR_PNC_07_Basefunction_CrossSection_5c9febde.GetCurrentPNCComMode
        OpEventGetCurrentPNCComMode_GetCurrentPNCComMode_UR_PNC_08_Basefunction_Connectivity_33115909: start-on-event=GetCurrentPNCComMode, operation=UR_PNC_08_Basefunction_Connectivity_33115909.GetCurrentPNCComMode
        OpEventGetCurrentPNCComMode_GetCurrentPNCComMode_UR_PNC_10_Powertrain_5fe7c550: start-on-event=GetCurrentPNCComMode, operation=UR_PNC_10_Powertrain_5fe7c550.GetCurrentPNCComMode
        OpEventGetCurrentPNCComMode_GetCurrentPNCComMode_UR_PNC_11_Chassis_fd87aaa6: start-on-event=GetCurrentPNCComMode, operation=UR_PNC_11_Chassis_fd87aaa6.GetCurrentPNCComMode
        OpEventGetCurrentPNCComMode_GetCurrentPNCComMode_UR_PNC_12_GearSelector_2aa5ddd0: start-on-event=GetCurrentPNCComMode, operation=UR_PNC_12_GearSelector_2aa5ddd0.GetCurrentPNCComMode
        OpEventGetCurrentPNCComMode_GetCurrentPNCComMode_UR_PNC_13_Airbag_2554061c: start-on-event=GetCurrentPNCComMode, operation=UR_PNC_13_Airbag_2554061c.GetCurrentPNCComMode
        OpEventGetCurrentPNCComMode_GetCurrentPNCComMode_UR_PNC_14_InfotainmentExtensions_d7c4346a: start-on-event=GetCurrentPNCComMode, operation=UR_PNC_14_InfotainmentExtensions_d7c4346a.GetCurrentPNCComMode
        OpEventGetCurrentPNCComMode_GetCurrentPNCComMode_UR_PNC_15_InstrumentclusterDisplay_1a610817: start-on-event=GetCurrentPNCComMode, operation=UR_PNC_15_InstrumentclusterDisplay_1a610817.GetCurrentPNCComMode
        OpEventGetCurrentPNCComMode_GetCurrentPNCComMode_UR_PNC_16_InfotainmentDisplay_1d18259d: start-on-event=GetCurrentPNCComMode, operation=UR_PNC_16_InfotainmentDisplay_1d18259d.GetCurrentPNCComMode
        OpEventGetCurrentPNCComMode_GetCurrentPNCComMode_UR_PNC_17_Audio_d11279f4: start-on-event=GetCurrentPNCComMode, operation=UR_PNC_17_Audio_d11279f4.GetCurrentPNCComMode
        OpEventGetCurrentPNCComMode_GetCurrentPNCComMode_UR_PNC_18_VirtualSideMirrors_dca4d4b3: start-on-event=GetCurrentPNCComMode, operation=UR_PNC_18_VirtualSideMirrors_dca4d4b3.GetCurrentPNCComMode
        OpEventGetCurrentPNCComMode_GetCurrentPNCComMode_UR_PNC_19_Doors_Hatches_58052c40: start-on-event=GetCurrentPNCComMode, operation=UR_PNC_19_Doors_Hatches_58052c40.GetCurrentPNCComMode
        OpEventGetCurrentPNCComMode_GetCurrentPNCComMode_UR_PNC_20_OptionalComfort_76e30655: start-on-event=GetCurrentPNCComMode, operation=UR_PNC_20_OptionalComfort_76e30655.GetCurrentPNCComMode
        OpEventGetCurrentPNCComMode_GetCurrentPNCComMode_UR_PNC_21_AirSuspension_3e4d6d03: start-on-event=GetCurrentPNCComMode, operation=UR_PNC_21_AirSuspension_3e4d6d03.GetCurrentPNCComMode
        OpEventGetCurrentPNCComMode_GetCurrentPNCComMode_UR_PNC_22_ExteriorLights_3bdfbcd3: start-on-event=GetCurrentPNCComMode, operation=UR_PNC_22_ExteriorLights_3bdfbcd3.GetCurrentPNCComMode
        OpEventGetCurrentPNCComMode_GetCurrentPNCComMode_UR_PNC_23_Climate_69d3b4ed: start-on-event=GetCurrentPNCComMode, operation=UR_PNC_23_Climate_69d3b4ed.GetCurrentPNCComMode
        OpEventGetCurrentPNCComMode_GetCurrentPNCComMode_UR_PNC_24_ThermoManagement_31b4f0b3: start-on-event=GetCurrentPNCComMode, operation=UR_PNC_24_ThermoManagement_31b4f0b3.GetCurrentPNCComMode
        OpEventGetCurrentPNCComMode_GetCurrentPNCComMode_UR_PNC_25_AccessSystemSensors_863389c2: start-on-event=GetCurrentPNCComMode, operation=UR_PNC_25_AccessSystemSensors_863389c2.GetCurrentPNCComMode
        OpEventGetCurrentPNCComMode_GetCurrentPNCComMode_UR_PNC_26_HighVoltage_Charging_c00f85a2: start-on-event=GetCurrentPNCComMode, operation=UR_PNC_26_HighVoltage_Charging_c00f85a2.GetCurrentPNCComMode
        OpEventGetCurrentPNCComMode_GetCurrentPNCComMode_UR_PNC_27_Timemaster_Timer_53539b48: start-on-event=GetCurrentPNCComMode, operation=UR_PNC_27_Timemaster_Timer_53539b48.GetCurrentPNCComMode
        OpEventGetCurrentPNCComMode_GetCurrentPNCComMode_UR_PNC_28_OnboardTester_DataCollector_c7d92e04: start-on-event=GetCurrentPNCComMode, operation=UR_PNC_28_OnboardTester_DataCollector_c7d92e04.GetCurrentPNCComMode
        OpEventGetCurrentPNCComMode_GetCurrentPNCComMode_UR_PNC_29_SteeringColumnLock_44a1738d: start-on-event=GetCurrentPNCComMode, operation=UR_PNC_29_SteeringColumnLock_44a1738d.GetCurrentPNCComMode
        OpEventGetCurrentPNCComMode_GetCurrentPNCComMode_UR_PNC_30_EnergyManagement_82f39188: start-on-event=GetCurrentPNCComMode, operation=UR_PNC_30_EnergyManagement_82f39188.GetCurrentPNCComMode
        OpEventGetCurrentPNCComMode_GetCurrentPNCComMode_UR_PNC_31_MultifunctionalSteeringWheel_48e6d667: start-on-event=GetCurrentPNCComMode, operation=UR_PNC_31_MultifunctionalSteeringWheel_48e6d667.GetCurrentPNCComMode
        OpEventGetCurrentPNCComMode_GetCurrentPNCComMode_UR_PNC_32_OnlineAccess_c5b851bc: start-on-event=GetCurrentPNCComMode, operation=UR_PNC_32_OnlineAccess_c5b851bc.GetCurrentPNCComMode
        OpEventGetCurrentPNCComMode_GetCurrentPNCComMode_UR_PNC_33_ExternalWirelessCommunication_779a8708: start-on-event=GetCurrentPNCComMode, operation=UR_PNC_33_ExternalWirelessCommunication_779a8708.GetCurrentPNCComMode
        OpEventGetCurrentPNCComMode_GetCurrentPNCComMode_UR_PNC_34_GPS_Lokalization_72b0f580: start-on-event=GetCurrentPNCComMode, operation=UR_PNC_34_GPS_Lokalization_72b0f580.GetCurrentPNCComMode
        OpEventGetCurrentPNCComMode_GetCurrentPNCComMode_UR_PNC_35_ExteriorSound_9764238b: start-on-event=GetCurrentPNCComMode, operation=UR_PNC_35_ExteriorSound_9764238b.GetCurrentPNCComMode
        OpEventGetCurrentPNCComMode_GetCurrentPNCComMode_UR_PNC_36_Preheater_5e289989: start-on-event=GetCurrentPNCComMode, operation=UR_PNC_36_Preheater_5e289989.GetCurrentPNCComMode
        OpEventGetCurrentPNCComMode_GetCurrentPNCComMode_UR_PNC_37_HighVoltage_WirelessChargingStation_f111c76f: start-on-event=GetCurrentPNCComMode, operation=UR_PNC_37_HighVoltage_WirelessChargingStation_f111c76f.GetCurrentPNCComMode
        OpEventGetCurrentPNCComMode_GetCurrentPNCComMode_UR_PNC_40_Diagnosis_Energy_532c6fb4: start-on-event=GetCurrentPNCComMode, operation=UR_PNC_40_Diagnosis_Energy_532c6fb4.GetCurrentPNCComMode
        OpEventGetCurrentPNCComMode_GetCurrentPNCComMode_UR_PNC_41_Diagnosis_Powertrain_0ac6ac8b: start-on-event=GetCurrentPNCComMode, operation=UR_PNC_41_Diagnosis_Powertrain_0ac6ac8b.GetCurrentPNCComMode
        OpEventGetCurrentPNCComMode_GetCurrentPNCComMode_UR_PNC_42_Diagnosis_FlexRay_f6dcf44d: start-on-event=GetCurrentPNCComMode, operation=UR_PNC_42_Diagnosis_FlexRay_f6dcf44d.GetCurrentPNCComMode
        OpEventGetCurrentPNCComMode_GetCurrentPNCComMode_UR_PNC_43_Diagnosis_DrivingAssistance_84f09039: start-on-event=GetCurrentPNCComMode, operation=UR_PNC_43_Diagnosis_DrivingAssistance_84f09039.GetCurrentPNCComMode
        OpEventGetCurrentPNCComMode_GetCurrentPNCComMode_UR_PNC_44_Diagnosis_Infotainment_3909218a: start-on-event=GetCurrentPNCComMode, operation=UR_PNC_44_Diagnosis_Infotainment_3909218a.GetCurrentPNCComMode
        OpEventGetCurrentPNCComMode_GetCurrentPNCComMode_UR_PNC_45_Diagnosis_Comfort_7eea372a: start-on-event=GetCurrentPNCComMode, operation=UR_PNC_45_Diagnosis_Comfort_7eea372a.GetCurrentPNCComMode
        OpEventGetCurrentPNCComMode_GetCurrentPNCComMode_UR_PNC_46_Diagnosis_Light_5140c135: start-on-event=GetCurrentPNCComMode, operation=UR_PNC_46_Diagnosis_Light_5140c135.GetCurrentPNCComMode
        OpEventGetCurrentPNCComMode_GetCurrentPNCComMode_UR_PNC_47_Diagnosis_ComfortLINs_70cf0372: start-on-event=GetCurrentPNCComMode, operation=UR_PNC_47_Diagnosis_ComfortLINs_70cf0372.GetCurrentPNCComMode
        OpEventGetCurrentPNCComMode_GetCurrentPNCComMode_UR_PNC_48_Diagnosis_ClimateTmeLINs_b4c40b49: start-on-event=GetCurrentPNCComMode, operation=UR_PNC_48_Diagnosis_ClimateTmeLINs_b4c40b49.GetCurrentPNCComMode
        OpEventGetCurrentPNCComMode_GetCurrentPNCComMode_UR_PNC_53_Lock_Unlock_bfb0b2ca: start-on-event=GetCurrentPNCComMode, operation=UR_PNC_53_Lock_Unlock_bfb0b2ca.GetCurrentPNCComMode
        OpEventGetCurrentPNCComMode_GetCurrentPNCComMode_UR_PNC_55_Dimming_4909a14c: start-on-event=GetCurrentPNCComMode, operation=UR_PNC_55_Dimming_4909a14c.GetCurrentPNCComMode
        OpEventGetCurrentPNCComMode_GetCurrentPNCComMode_UR_PNC_56_Charging_Status_cad5dfb4: start-on-event=GetCurrentPNCComMode, operation=UR_PNC_56_Charging_Status_cad5dfb4.GetCurrentPNCComMode
        OpEventGetMaxComMode_GetMaxComMode_UR_CN_BMC_CAN01_908d0059: start-on-event=GetMaxComMode, operation=UR_CN_BMC_CAN01_908d0059.GetMaxComMode
        OpEventGetMaxComMode_GetMaxComMode_UR_CN_HCP5_CANFD01_84d44928: start-on-event=GetMaxComMode, operation=UR_CN_HCP5_CANFD01_84d44928.GetMaxComMode
        OpEventGetMaxComMode_GetMaxComMode_UR_PNC_01_CarWakeUp_bf3ce487: start-on-event=GetMaxComMode, operation=UR_PNC_01_CarWakeUp_bf3ce487.GetMaxComMode
        OpEventGetMaxComMode_GetMaxComMode_UR_PNC_02_Basefunction_Powertrain_6e8e3f0b: start-on-event=GetMaxComMode, operation=UR_PNC_02_Basefunction_Powertrain_6e8e3f0b.GetMaxComMode
        OpEventGetMaxComMode_GetMaxComMode_UR_PNC_03_Basefunction_Chassis_74381a7a: start-on-event=GetMaxComMode, operation=UR_PNC_03_Basefunction_Chassis_74381a7a.GetMaxComMode
        OpEventGetMaxComMode_GetMaxComMode_UR_PNC_04_Basefunction_DrivingAssistance_2e755e80: start-on-event=GetMaxComMode, operation=UR_PNC_04_Basefunction_DrivingAssistance_2e755e80.GetMaxComMode
        OpEventGetMaxComMode_GetMaxComMode_UR_PNC_05_Basefunction_Infotainment_d739ca28: start-on-event=GetMaxComMode, operation=UR_PNC_05_Basefunction_Infotainment_d739ca28.GetMaxComMode
        OpEventGetMaxComMode_GetMaxComMode_UR_PNC_06_Basefunction_ComfortLight_8074acb0: start-on-event=GetMaxComMode, operation=UR_PNC_06_Basefunction_ComfortLight_8074acb0.GetMaxComMode
        OpEventGetMaxComMode_GetMaxComMode_UR_PNC_07_Basefunction_CrossSection_5c9febde: start-on-event=GetMaxComMode, operation=UR_PNC_07_Basefunction_CrossSection_5c9febde.GetMaxComMode
        OpEventGetMaxComMode_GetMaxComMode_UR_PNC_08_Basefunction_Connectivity_33115909: start-on-event=GetMaxComMode, operation=UR_PNC_08_Basefunction_Connectivity_33115909.GetMaxComMode
        OpEventGetMaxComMode_GetMaxComMode_UR_PNC_10_Powertrain_5fe7c550: start-on-event=GetMaxComMode, operation=UR_PNC_10_Powertrain_5fe7c550.GetMaxComMode
        OpEventGetMaxComMode_GetMaxComMode_UR_PNC_11_Chassis_fd87aaa6: start-on-event=GetMaxComMode, operation=UR_PNC_11_Chassis_fd87aaa6.GetMaxComMode
        OpEventGetMaxComMode_GetMaxComMode_UR_PNC_12_GearSelector_2aa5ddd0: start-on-event=GetMaxComMode, operation=UR_PNC_12_GearSelector_2aa5ddd0.GetMaxComMode
        OpEventGetMaxComMode_GetMaxComMode_UR_PNC_13_Airbag_2554061c: start-on-event=GetMaxComMode, operation=UR_PNC_13_Airbag_2554061c.GetMaxComMode
        OpEventGetMaxComMode_GetMaxComMode_UR_PNC_14_InfotainmentExtensions_d7c4346a: start-on-event=GetMaxComMode, operation=UR_PNC_14_InfotainmentExtensions_d7c4346a.GetMaxComMode
        OpEventGetMaxComMode_GetMaxComMode_UR_PNC_15_InstrumentclusterDisplay_1a610817: start-on-event=GetMaxComMode, operation=UR_PNC_15_InstrumentclusterDisplay_1a610817.GetMaxComMode
        OpEventGetMaxComMode_GetMaxComMode_UR_PNC_16_InfotainmentDisplay_1d18259d: start-on-event=GetMaxComMode, operation=UR_PNC_16_InfotainmentDisplay_1d18259d.GetMaxComMode
        OpEventGetMaxComMode_GetMaxComMode_UR_PNC_17_Audio_d11279f4: start-on-event=GetMaxComMode, operation=UR_PNC_17_Audio_d11279f4.GetMaxComMode
        OpEventGetMaxComMode_GetMaxComMode_UR_PNC_18_VirtualSideMirrors_dca4d4b3: start-on-event=GetMaxComMode, operation=UR_PNC_18_VirtualSideMirrors_dca4d4b3.GetMaxComMode
        OpEventGetMaxComMode_GetMaxComMode_UR_PNC_19_Doors_Hatches_58052c40: start-on-event=GetMaxComMode, operation=UR_PNC_19_Doors_Hatches_58052c40.GetMaxComMode
        OpEventGetMaxComMode_GetMaxComMode_UR_PNC_20_OptionalComfort_76e30655: start-on-event=GetMaxComMode, operation=UR_PNC_20_OptionalComfort_76e30655.GetMaxComMode
        OpEventGetMaxComMode_GetMaxComMode_UR_PNC_21_AirSuspension_3e4d6d03: start-on-event=GetMaxComMode, operation=UR_PNC_21_AirSuspension_3e4d6d03.GetMaxComMode
        OpEventGetMaxComMode_GetMaxComMode_UR_PNC_22_ExteriorLights_3bdfbcd3: start-on-event=GetMaxComMode, operation=UR_PNC_22_ExteriorLights_3bdfbcd3.GetMaxComMode
        OpEventGetMaxComMode_GetMaxComMode_UR_PNC_23_Climate_69d3b4ed: start-on-event=GetMaxComMode, operation=UR_PNC_23_Climate_69d3b4ed.GetMaxComMode
        OpEventGetMaxComMode_GetMaxComMode_UR_PNC_24_ThermoManagement_31b4f0b3: start-on-event=GetMaxComMode, operation=UR_PNC_24_ThermoManagement_31b4f0b3.GetMaxComMode
        OpEventGetMaxComMode_GetMaxComMode_UR_PNC_25_AccessSystemSensors_863389c2: start-on-event=GetMaxComMode, operation=UR_PNC_25_AccessSystemSensors_863389c2.GetMaxComMode
        OpEventGetMaxComMode_GetMaxComMode_UR_PNC_26_HighVoltage_Charging_c00f85a2: start-on-event=GetMaxComMode, operation=UR_PNC_26_HighVoltage_Charging_c00f85a2.GetMaxComMode
        OpEventGetMaxComMode_GetMaxComMode_UR_PNC_27_Timemaster_Timer_53539b48: start-on-event=GetMaxComMode, operation=UR_PNC_27_Timemaster_Timer_53539b48.GetMaxComMode
        OpEventGetMaxComMode_GetMaxComMode_UR_PNC_28_OnboardTester_DataCollector_c7d92e04: start-on-event=GetMaxComMode, operation=UR_PNC_28_OnboardTester_DataCollector_c7d92e04.GetMaxComMode
        OpEventGetMaxComMode_GetMaxComMode_UR_PNC_29_SteeringColumnLock_44a1738d: start-on-event=GetMaxComMode, operation=UR_PNC_29_SteeringColumnLock_44a1738d.GetMaxComMode
        OpEventGetMaxComMode_GetMaxComMode_UR_PNC_30_EnergyManagement_82f39188: start-on-event=GetMaxComMode, operation=UR_PNC_30_EnergyManagement_82f39188.GetMaxComMode
        OpEventGetMaxComMode_GetMaxComMode_UR_PNC_31_MultifunctionalSteeringWheel_48e6d667: start-on-event=GetMaxComMode, operation=UR_PNC_31_MultifunctionalSteeringWheel_48e6d667.GetMaxComMode
        OpEventGetMaxComMode_GetMaxComMode_UR_PNC_32_OnlineAccess_c5b851bc: start-on-event=GetMaxComMode, operation=UR_PNC_32_OnlineAccess_c5b851bc.GetMaxComMode
        OpEventGetMaxComMode_GetMaxComMode_UR_PNC_33_ExternalWirelessCommunication_779a8708: start-on-event=GetMaxComMode, operation=UR_PNC_33_ExternalWirelessCommunication_779a8708.GetMaxComMode
        OpEventGetMaxComMode_GetMaxComMode_UR_PNC_34_GPS_Lokalization_72b0f580: start-on-event=GetMaxComMode, operation=UR_PNC_34_GPS_Lokalization_72b0f580.GetMaxComMode
        OpEventGetMaxComMode_GetMaxComMode_UR_PNC_35_ExteriorSound_9764238b: start-on-event=GetMaxComMode, operation=UR_PNC_35_ExteriorSound_9764238b.GetMaxComMode
        OpEventGetMaxComMode_GetMaxComMode_UR_PNC_36_Preheater_5e289989: start-on-event=GetMaxComMode, operation=UR_PNC_36_Preheater_5e289989.GetMaxComMode
        OpEventGetMaxComMode_GetMaxComMode_UR_PNC_37_HighVoltage_WirelessChargingStation_f111c76f: start-on-event=GetMaxComMode, operation=UR_PNC_37_HighVoltage_WirelessChargingStation_f111c76f.GetMaxComMode
        OpEventGetMaxComMode_GetMaxComMode_UR_PNC_40_Diagnosis_Energy_532c6fb4: start-on-event=GetMaxComMode, operation=UR_PNC_40_Diagnosis_Energy_532c6fb4.GetMaxComMode
        OpEventGetMaxComMode_GetMaxComMode_UR_PNC_41_Diagnosis_Powertrain_0ac6ac8b: start-on-event=GetMaxComMode, operation=UR_PNC_41_Diagnosis_Powertrain_0ac6ac8b.GetMaxComMode
        OpEventGetMaxComMode_GetMaxComMode_UR_PNC_42_Diagnosis_FlexRay_f6dcf44d: start-on-event=GetMaxComMode, operation=UR_PNC_42_Diagnosis_FlexRay_f6dcf44d.GetMaxComMode
        OpEventGetMaxComMode_GetMaxComMode_UR_PNC_43_Diagnosis_DrivingAssistance_84f09039: start-on-event=GetMaxComMode, operation=UR_PNC_43_Diagnosis_DrivingAssistance_84f09039.GetMaxComMode
        OpEventGetMaxComMode_GetMaxComMode_UR_PNC_44_Diagnosis_Infotainment_3909218a: start-on-event=GetMaxComMode, operation=UR_PNC_44_Diagnosis_Infotainment_3909218a.GetMaxComMode
        OpEventGetMaxComMode_GetMaxComMode_UR_PNC_45_Diagnosis_Comfort_7eea372a: start-on-event=GetMaxComMode, operation=UR_PNC_45_Diagnosis_Comfort_7eea372a.GetMaxComMode
        OpEventGetMaxComMode_GetMaxComMode_UR_PNC_46_Diagnosis_Light_5140c135: start-on-event=GetMaxComMode, operation=UR_PNC_46_Diagnosis_Light_5140c135.GetMaxComMode
        OpEventGetMaxComMode_GetMaxComMode_UR_PNC_47_Diagnosis_ComfortLINs_70cf0372: start-on-event=GetMaxComMode, operation=UR_PNC_47_Diagnosis_ComfortLINs_70cf0372.GetMaxComMode
        OpEventGetMaxComMode_GetMaxComMode_UR_PNC_48_Diagnosis_ClimateTmeLINs_b4c40b49: start-on-event=GetMaxComMode, operation=UR_PNC_48_Diagnosis_ClimateTmeLINs_b4c40b49.GetMaxComMode
        OpEventGetMaxComMode_GetMaxComMode_UR_PNC_53_Lock_Unlock_bfb0b2ca: start-on-event=GetMaxComMode, operation=UR_PNC_53_Lock_Unlock_bfb0b2ca.GetMaxComMode
        OpEventGetMaxComMode_GetMaxComMode_UR_PNC_55_Dimming_4909a14c: start-on-event=GetMaxComMode, operation=UR_PNC_55_Dimming_4909a14c.GetMaxComMode
        OpEventGetMaxComMode_GetMaxComMode_UR_PNC_56_Charging_Status_cad5dfb4: start-on-event=GetMaxComMode, operation=UR_PNC_56_Charging_Status_cad5dfb4.GetMaxComMode
        OpEventGetRequestedComMode_GetRequestedComMode_UR_CN_BMC_CAN01_908d0059: start-on-event=GetRequestedComMode, operation=UR_CN_BMC_CAN01_908d0059.GetRequestedComMode
        OpEventGetRequestedComMode_GetRequestedComMode_UR_CN_HCP5_CANFD01_84d44928: start-on-event=GetRequestedComMode, operation=UR_CN_HCP5_CANFD01_84d44928.GetRequestedComMode
        OpEventGetRequestedComMode_GetRequestedComMode_UR_PNC_01_CarWakeUp_bf3ce487: start-on-event=GetRequestedComMode, operation=UR_PNC_01_CarWakeUp_bf3ce487.GetRequestedComMode
        OpEventGetRequestedComMode_GetRequestedComMode_UR_PNC_02_Basefunction_Powertrain_6e8e3f0b: start-on-event=GetRequestedComMode, operation=UR_PNC_02_Basefunction_Powertrain_6e8e3f0b.GetRequestedComMode
        OpEventGetRequestedComMode_GetRequestedComMode_UR_PNC_03_Basefunction_Chassis_74381a7a: start-on-event=GetRequestedComMode, operation=UR_PNC_03_Basefunction_Chassis_74381a7a.GetRequestedComMode
        OpEventGetRequestedComMode_GetRequestedComMode_UR_PNC_04_Basefunction_DrivingAssistance_2e755e80: start-on-event=GetRequestedComMode, operation=UR_PNC_04_Basefunction_DrivingAssistance_2e755e80.GetRequestedComMode
        OpEventGetRequestedComMode_GetRequestedComMode_UR_PNC_05_Basefunction_Infotainment_d739ca28: start-on-event=GetRequestedComMode, operation=UR_PNC_05_Basefunction_Infotainment_d739ca28.GetRequestedComMode
        OpEventGetRequestedComMode_GetRequestedComMode_UR_PNC_06_Basefunction_ComfortLight_8074acb0: start-on-event=GetRequestedComMode, operation=UR_PNC_06_Basefunction_ComfortLight_8074acb0.GetRequestedComMode
        OpEventGetRequestedComMode_GetRequestedComMode_UR_PNC_07_Basefunction_CrossSection_5c9febde: start-on-event=GetRequestedComMode, operation=UR_PNC_07_Basefunction_CrossSection_5c9febde.GetRequestedComMode
        OpEventGetRequestedComMode_GetRequestedComMode_UR_PNC_08_Basefunction_Connectivity_33115909: start-on-event=GetRequestedComMode, operation=UR_PNC_08_Basefunction_Connectivity_33115909.GetRequestedComMode
        OpEventGetRequestedComMode_GetRequestedComMode_UR_PNC_10_Powertrain_5fe7c550: start-on-event=GetRequestedComMode, operation=UR_PNC_10_Powertrain_5fe7c550.GetRequestedComMode
        OpEventGetRequestedComMode_GetRequestedComMode_UR_PNC_11_Chassis_fd87aaa6: start-on-event=GetRequestedComMode, operation=UR_PNC_11_Chassis_fd87aaa6.GetRequestedComMode
        OpEventGetRequestedComMode_GetRequestedComMode_UR_PNC_12_GearSelector_2aa5ddd0: start-on-event=GetRequestedComMode, operation=UR_PNC_12_GearSelector_2aa5ddd0.GetRequestedComMode
        OpEventGetRequestedComMode_GetRequestedComMode_UR_PNC_13_Airbag_2554061c: start-on-event=GetRequestedComMode, operation=UR_PNC_13_Airbag_2554061c.GetRequestedComMode
        OpEventGetRequestedComMode_GetRequestedComMode_UR_PNC_14_InfotainmentExtensions_d7c4346a: start-on-event=GetRequestedComMode, operation=UR_PNC_14_InfotainmentExtensions_d7c4346a.GetRequestedComMode
        OpEventGetRequestedComMode_GetRequestedComMode_UR_PNC_15_InstrumentclusterDisplay_1a610817: start-on-event=GetRequestedComMode, operation=UR_PNC_15_InstrumentclusterDisplay_1a610817.GetRequestedComMode
        OpEventGetRequestedComMode_GetRequestedComMode_UR_PNC_16_InfotainmentDisplay_1d18259d: start-on-event=GetRequestedComMode, operation=UR_PNC_16_InfotainmentDisplay_1d18259d.GetRequestedComMode
        OpEventGetRequestedComMode_GetRequestedComMode_UR_PNC_17_Audio_d11279f4: start-on-event=GetRequestedComMode, operation=UR_PNC_17_Audio_d11279f4.GetRequestedComMode
        OpEventGetRequestedComMode_GetRequestedComMode_UR_PNC_18_VirtualSideMirrors_dca4d4b3: start-on-event=GetRequestedComMode, operation=UR_PNC_18_VirtualSideMirrors_dca4d4b3.GetRequestedComMode
        OpEventGetRequestedComMode_GetRequestedComMode_UR_PNC_19_Doors_Hatches_58052c40: start-on-event=GetRequestedComMode, operation=UR_PNC_19_Doors_Hatches_58052c40.GetRequestedComMode
        OpEventGetRequestedComMode_GetRequestedComMode_UR_PNC_20_OptionalComfort_76e30655: start-on-event=GetRequestedComMode, operation=UR_PNC_20_OptionalComfort_76e30655.GetRequestedComMode
        OpEventGetRequestedComMode_GetRequestedComMode_UR_PNC_21_AirSuspension_3e4d6d03: start-on-event=GetRequestedComMode, operation=UR_PNC_21_AirSuspension_3e4d6d03.GetRequestedComMode
        OpEventGetRequestedComMode_GetRequestedComMode_UR_PNC_22_ExteriorLights_3bdfbcd3: start-on-event=GetRequestedComMode, operation=UR_PNC_22_ExteriorLights_3bdfbcd3.GetRequestedComMode
        OpEventGetRequestedComMode_GetRequestedComMode_UR_PNC_23_Climate_69d3b4ed: start-on-event=GetRequestedComMode, operation=UR_PNC_23_Climate_69d3b4ed.GetRequestedComMode
        OpEventGetRequestedComMode_GetRequestedComMode_UR_PNC_24_ThermoManagement_31b4f0b3: start-on-event=GetRequestedComMode, operation=UR_PNC_24_ThermoManagement_31b4f0b3.GetRequestedComMode
        OpEventGetRequestedComMode_GetRequestedComMode_UR_PNC_25_AccessSystemSensors_863389c2: start-on-event=GetRequestedComMode, operation=UR_PNC_25_AccessSystemSensors_863389c2.GetRequestedComMode
        OpEventGetRequestedComMode_GetRequestedComMode_UR_PNC_26_HighVoltage_Charging_c00f85a2: start-on-event=GetRequestedComMode, operation=UR_PNC_26_HighVoltage_Charging_c00f85a2.GetRequestedComMode
        OpEventGetRequestedComMode_GetRequestedComMode_UR_PNC_27_Timemaster_Timer_53539b48: start-on-event=GetRequestedComMode, operation=UR_PNC_27_Timemaster_Timer_53539b48.GetRequestedComMode
        OpEventGetRequestedComMode_GetRequestedComMode_UR_PNC_28_OnboardTester_DataCollector_c7d92e04: start-on-event=GetRequestedComMode, operation=UR_PNC_28_OnboardTester_DataCollector_c7d92e04.GetRequestedComMode
        OpEventGetRequestedComMode_GetRequestedComMode_UR_PNC_29_SteeringColumnLock_44a1738d: start-on-event=GetRequestedComMode, operation=UR_PNC_29_SteeringColumnLock_44a1738d.GetRequestedComMode
        OpEventGetRequestedComMode_GetRequestedComMode_UR_PNC_30_EnergyManagement_82f39188: start-on-event=GetRequestedComMode, operation=UR_PNC_30_EnergyManagement_82f39188.GetRequestedComMode
        OpEventGetRequestedComMode_GetRequestedComMode_UR_PNC_31_MultifunctionalSteeringWheel_48e6d667: start-on-event=GetRequestedComMode, operation=UR_PNC_31_MultifunctionalSteeringWheel_48e6d667.GetRequestedComMode
        OpEventGetRequestedComMode_GetRequestedComMode_UR_PNC_32_OnlineAccess_c5b851bc: start-on-event=GetRequestedComMode, operation=UR_PNC_32_OnlineAccess_c5b851bc.GetRequestedComMode
        OpEventGetRequestedComMode_GetRequestedComMode_UR_PNC_33_ExternalWirelessCommunication_779a8708: start-on-event=GetRequestedComMode, operation=UR_PNC_33_ExternalWirelessCommunication_779a8708.GetRequestedComMode
        OpEventGetRequestedComMode_GetRequestedComMode_UR_PNC_34_GPS_Lokalization_72b0f580: start-on-event=GetRequestedComMode, operation=UR_PNC_34_GPS_Lokalization_72b0f580.GetRequestedComMode
        OpEventGetRequestedComMode_GetRequestedComMode_UR_PNC_35_ExteriorSound_9764238b: start-on-event=GetRequestedComMode, operation=UR_PNC_35_ExteriorSound_9764238b.GetRequestedComMode
        OpEventGetRequestedComMode_GetRequestedComMode_UR_PNC_36_Preheater_5e289989: start-on-event=GetRequestedComMode, operation=UR_PNC_36_Preheater_5e289989.GetRequestedComMode
        OpEventGetRequestedComMode_GetRequestedComMode_UR_PNC_37_HighVoltage_WirelessChargingStation_f111c76f: start-on-event=GetRequestedComMode, operation=UR_PNC_37_HighVoltage_WirelessChargingStation_f111c76f.GetRequestedComMode
        OpEventGetRequestedComMode_GetRequestedComMode_UR_PNC_40_Diagnosis_Energy_532c6fb4: start-on-event=GetRequestedComMode, operation=UR_PNC_40_Diagnosis_Energy_532c6fb4.GetRequestedComMode
        OpEventGetRequestedComMode_GetRequestedComMode_UR_PNC_41_Diagnosis_Powertrain_0ac6ac8b: start-on-event=GetRequestedComMode, operation=UR_PNC_41_Diagnosis_Powertrain_0ac6ac8b.GetRequestedComMode
        OpEventGetRequestedComMode_GetRequestedComMode_UR_PNC_42_Diagnosis_FlexRay_f6dcf44d: start-on-event=GetRequestedComMode, operation=UR_PNC_42_Diagnosis_FlexRay_f6dcf44d.GetRequestedComMode
        OpEventGetRequestedComMode_GetRequestedComMode_UR_PNC_43_Diagnosis_DrivingAssistance_84f09039: start-on-event=GetRequestedComMode, operation=UR_PNC_43_Diagnosis_DrivingAssistance_84f09039.GetRequestedComMode
        OpEventGetRequestedComMode_GetRequestedComMode_UR_PNC_44_Diagnosis_Infotainment_3909218a: start-on-event=GetRequestedComMode, operation=UR_PNC_44_Diagnosis_Infotainment_3909218a.GetRequestedComMode
        OpEventGetRequestedComMode_GetRequestedComMode_UR_PNC_45_Diagnosis_Comfort_7eea372a: start-on-event=GetRequestedComMode, operation=UR_PNC_45_Diagnosis_Comfort_7eea372a.GetRequestedComMode
        OpEventGetRequestedComMode_GetRequestedComMode_UR_PNC_46_Diagnosis_Light_5140c135: start-on-event=GetRequestedComMode, operation=UR_PNC_46_Diagnosis_Light_5140c135.GetRequestedComMode
        OpEventGetRequestedComMode_GetRequestedComMode_UR_PNC_47_Diagnosis_ComfortLINs_70cf0372: start-on-event=GetRequestedComMode, operation=UR_PNC_47_Diagnosis_ComfortLINs_70cf0372.GetRequestedComMode
        OpEventGetRequestedComMode_GetRequestedComMode_UR_PNC_48_Diagnosis_ClimateTmeLINs_b4c40b49: start-on-event=GetRequestedComMode, operation=UR_PNC_48_Diagnosis_ClimateTmeLINs_b4c40b49.GetRequestedComMode
        OpEventGetRequestedComMode_GetRequestedComMode_UR_PNC_53_Lock_Unlock_bfb0b2ca: start-on-event=GetRequestedComMode, operation=UR_PNC_53_Lock_Unlock_bfb0b2ca.GetRequestedComMode
        OpEventGetRequestedComMode_GetRequestedComMode_UR_PNC_55_Dimming_4909a14c: start-on-event=GetRequestedComMode, operation=UR_PNC_55_Dimming_4909a14c.GetRequestedComMode
        OpEventGetRequestedComMode_GetRequestedComMode_UR_PNC_56_Charging_Status_cad5dfb4: start-on-event=GetRequestedComMode, operation=UR_PNC_56_Charging_Status_cad5dfb4.GetRequestedComMode
      port-api-options:
        enable-take-address=true, indirect-api=false, port=modeLimitation
        {enable-take-address=true, indirect-api=false, port-defined-argument-value{value=0, value-type=NetworkHandleType}, port=CL_CN_BMC_CAN01_78a85e89}
        {enable-take-address=true, indirect-api=false, port-defined-argument-value{value=0, value-type=NetworkHandleType}, port=CW_CN_BMC_CAN01_78a85e89}
        {enable-take-address=true, indirect-api=false, port-defined-argument-value{value=1, value-type=NetworkHandleType}, port=CL_CN_HCP5_CANFD01_54d90215}
        {enable-take-address=true, indirect-api=false, port-defined-argument-value{value=1, value-type=NetworkHandleType}, port=CW_CN_HCP5_CANFD01_54d90215}
        {enable-take-address=true, indirect-api=false, port-defined-argument-value{value=0, value-type=ComM_UserHandleType}, port=UR_CN_BMC_CAN01_908d0059}
        {enable-take-address=true, indirect-api=false, port-defined-argument-value{value=1, value-type=ComM_UserHandleType}, port=UR_CN_HCP5_CANFD01_84d44928}
        {enable-take-address=true, indirect-api=false, port-defined-argument-value{value=2, value-type=ComM_UserHandleType}, port=UR_PNC_01_CarWakeUp_bf3ce487}
        {enable-take-address=true, indirect-api=false, port-defined-argument-value{value=3, value-type=ComM_UserHandleType}, port=UR_PNC_02_Basefunction_Powertrain_6e8e3f0b}
        {enable-take-address=true, indirect-api=false, port-defined-argument-value{value=4, value-type=ComM_UserHandleType}, port=UR_PNC_03_Basefunction_Chassis_74381a7a}
        {enable-take-address=true, indirect-api=false, port-defined-argument-value{value=5, value-type=ComM_UserHandleType}, port=UR_PNC_04_Basefunction_DrivingAssistance_2e755e80}
        {enable-take-address=true, indirect-api=false, port-defined-argument-value{value=6, value-type=ComM_UserHandleType}, port=UR_PNC_05_Basefunction_Infotainment_d739ca28}
        {enable-take-address=true, indirect-api=false, port-defined-argument-value{value=7, value-type=ComM_UserHandleType}, port=UR_PNC_06_Basefunction_ComfortLight_8074acb0}
        {enable-take-address=true, indirect-api=false, port-defined-argument-value{value=8, value-type=ComM_UserHandleType}, port=UR_PNC_07_Basefunction_CrossSection_5c9febde}
        {enable-take-address=true, indirect-api=false, port-defined-argument-value{value=9, value-type=ComM_UserHandleType}, port=UR_PNC_08_Basefunction_Connectivity_33115909}
        {enable-take-address=true, indirect-api=false, port-defined-argument-value{value=10, value-type=ComM_UserHandleType}, port=UR_PNC_10_Powertrain_5fe7c550}
        {enable-take-address=true, indirect-api=false, port-defined-argument-value{value=11, value-type=ComM_UserHandleType}, port=UR_PNC_11_Chassis_fd87aaa6}
        {enable-take-address=true, indirect-api=false, port-defined-argument-value{value=12, value-type=ComM_UserHandleType}, port=UR_PNC_12_GearSelector_2aa5ddd0}
        {enable-take-address=true, indirect-api=false, port-defined-argument-value{value=13, value-type=ComM_UserHandleType}, port=UR_PNC_13_Airbag_2554061c}
        {enable-take-address=true, indirect-api=false, port-defined-argument-value{value=14, value-type=ComM_UserHandleType}, port=UR_PNC_14_InfotainmentExtensions_d7c4346a}
        {enable-take-address=true, indirect-api=false, port-defined-argument-value{value=15, value-type=ComM_UserHandleType}, port=UR_PNC_15_InstrumentclusterDisplay_1a610817}
        {enable-take-address=true, indirect-api=false, port-defined-argument-value{value=16, value-type=ComM_UserHandleType}, port=UR_PNC_16_InfotainmentDisplay_1d18259d}
        {enable-take-address=true, indirect-api=false, port-defined-argument-value{value=17, value-type=ComM_UserHandleType}, port=UR_PNC_17_Audio_d11279f4}
        {enable-take-address=true, indirect-api=false, port-defined-argument-value{value=18, value-type=ComM_UserHandleType}, port=UR_PNC_18_VirtualSideMirrors_dca4d4b3}
        {enable-take-address=true, indirect-api=false, port-defined-argument-value{value=19, value-type=ComM_UserHandleType}, port=UR_PNC_19_Doors_Hatches_58052c40}
        {enable-take-address=true, indirect-api=false, port-defined-argument-value{value=20, value-type=ComM_UserHandleType}, port=UR_PNC_20_OptionalComfort_76e30655}
        {enable-take-address=true, indirect-api=false, port-defined-argument-value{value=21, value-type=ComM_UserHandleType}, port=UR_PNC_21_AirSuspension_3e4d6d03}
        {enable-take-address=true, indirect-api=false, port-defined-argument-value{value=22, value-type=ComM_UserHandleType}, port=UR_PNC_22_ExteriorLights_3bdfbcd3}
        {enable-take-address=true, indirect-api=false, port-defined-argument-value{value=23, value-type=ComM_UserHandleType}, port=UR_PNC_23_Climate_69d3b4ed}
        {enable-take-address=true, indirect-api=false, port-defined-argument-value{value=24, value-type=ComM_UserHandleType}, port=UR_PNC_24_ThermoManagement_31b4f0b3}
        {enable-take-address=true, indirect-api=false, port-defined-argument-value{value=25, value-type=ComM_UserHandleType}, port=UR_PNC_25_AccessSystemSensors_863389c2}
        {enable-take-address=true, indirect-api=false, port-defined-argument-value{value=26, value-type=ComM_UserHandleType}, port=UR_PNC_26_HighVoltage_Charging_c00f85a2}
        {enable-take-address=true, indirect-api=false, port-defined-argument-value{value=27, value-type=ComM_UserHandleType}, port=UR_PNC_27_Timemaster_Timer_53539b48}
        {enable-take-address=true, indirect-api=false, port-defined-argument-value{value=28, value-type=ComM_UserHandleType}, port=UR_PNC_28_OnboardTester_DataCollector_c7d92e04}
        {enable-take-address=true, indirect-api=false, port-defined-argument-value{value=29, value-type=ComM_UserHandleType}, port=UR_PNC_29_SteeringColumnLock_44a1738d}
        {enable-take-address=true, indirect-api=false, port-defined-argument-value{value=30, value-type=ComM_UserHandleType}, port=UR_PNC_30_EnergyManagement_82f39188}
        {enable-take-address=true, indirect-api=false, port-defined-argument-value{value=31, value-type=ComM_UserHandleType}, port=UR_PNC_31_MultifunctionalSteeringWheel_48e6d667}
        {enable-take-address=true, indirect-api=false, port-defined-argument-value{value=32, value-type=ComM_UserHandleType}, port=UR_PNC_32_OnlineAccess_c5b851bc}
        {enable-take-address=true, indirect-api=false, port-defined-argument-value{value=33, value-type=ComM_UserHandleType}, port=UR_PNC_33_ExternalWirelessCommunication_779a8708}
        {enable-take-address=true, indirect-api=false, port-defined-argument-value{value=34, value-type=ComM_UserHandleType}, port=UR_PNC_34_GPS_Lokalization_72b0f580}
        {enable-take-address=true, indirect-api=false, port-defined-argument-value{value=35, value-type=ComM_UserHandleType}, port=UR_PNC_35_ExteriorSound_9764238b}
        {enable-take-address=true, indirect-api=false, port-defined-argument-value{value=36, value-type=ComM_UserHandleType}, port=UR_PNC_36_Preheater_5e289989}
        {enable-take-address=true, indirect-api=false, port-defined-argument-value{value=37, value-type=ComM_UserHandleType}, port=UR_PNC_37_HighVoltage_WirelessChargingStation_f111c76f}
        {enable-take-address=true, indirect-api=false, port-defined-argument-value{value=38, value-type=ComM_UserHandleType}, port=UR_PNC_40_Diagnosis_Energy_532c6fb4}
        {enable-take-address=true, indirect-api=false, port-defined-argument-value{value=39, value-type=ComM_UserHandleType}, port=UR_PNC_41_Diagnosis_Powertrain_0ac6ac8b}
        {enable-take-address=true, indirect-api=false, port-defined-argument-value{value=40, value-type=ComM_UserHandleType}, port=UR_PNC_42_Diagnosis_FlexRay_f6dcf44d}
        {enable-take-address=true, indirect-api=false, port-defined-argument-value{value=41, value-type=ComM_UserHandleType}, port=UR_PNC_43_Diagnosis_DrivingAssistance_84f09039}
        {enable-take-address=true, indirect-api=false, port-defined-argument-value{value=42, value-type=ComM_UserHandleType}, port=UR_PNC_44_Diagnosis_Infotainment_3909218a}
        {enable-take-address=true, indirect-api=false, port-defined-argument-value{value=43, value-type=ComM_UserHandleType}, port=UR_PNC_45_Diagnosis_Comfort_7eea372a}
        {enable-take-address=true, indirect-api=false, port-defined-argument-value{value=44, value-type=ComM_UserHandleType}, port=UR_PNC_46_Diagnosis_Light_5140c135}
        {enable-take-address=true, indirect-api=false, port-defined-argument-value{value=45, value-type=ComM_UserHandleType}, port=UR_PNC_47_Diagnosis_ComfortLINs_70cf0372}
        {enable-take-address=true, indirect-api=false, port-defined-argument-value{value=46, value-type=ComM_UserHandleType}, port=UR_PNC_48_Diagnosis_ClimateTmeLINs_b4c40b49}
        {enable-take-address=true, indirect-api=false, port-defined-argument-value{value=47, value-type=ComM_UserHandleType}, port=UR_PNC_53_Lock_Unlock_bfb0b2ca}
        {enable-take-address=true, indirect-api=false, port-defined-argument-value{value=48, value-type=ComM_UserHandleType}, port=UR_PNC_55_Dimming_4909a14c}
        {enable-take-address=true, indirect-api=false, port-defined-argument-value{value=49, value-type=ComM_UserHandleType}, port=UR_PNC_56_Charging_Status_cad5dfb4}
      14 x runnable, all with can-be-invoked-concurrently=true:
        ComM_MainFunction_0
        ComM_MainFunction_1
        GetInhibitionStatus: symbol=ComM_GetInhibitionStatus
        LimitECUToNoComMode: symbol=ComM_LimitECUToNoComMode
        ReadInhibitCounter: symbol=ComM_ReadInhibitCounter
        ResetInhibitCounter: symbol=ComM_ResetInhibitCounter
        SetECUGroupClassification: symbol=ComM_SetECUGroupClassification
        LimitChannelToNoComMode: symbol=ComM_LimitChannelToNoComMode
        PreventWakeUp: symbol=ComM_PreventWakeUp
        RequestComMode: symbol=ComM_RequestComMode
        GetCurrentComMode: symbol=ComM_GetCurrentComMode
        GetMaxComMode: symbol=ComM_GetMaxComMode
        GetRequestedComMode: symbol=ComM_GetRequestedComMode
        GetCurrentPNCComMode: symbol=ComM_GetCurrentPNCComMode
  swc implementation ComMImplementation: programming-language=C, behavior=ComMInternalBehavior
    resource consumption ComMResourceConsumption
      5 x memory section:
        ComM_START_SEC_CODE: sw-addrmethod=CODE, symbol=CODE
        ComM_START_SEC_CONST_UNSPECIFIED: alignment=UNSPECIFIED, sw-addrmethod=CONST, symbol=CONST_UNSPECIFIED
        ComM_START_SEC_VAR_NOINIT_UNSPECIFIED: alignment=UNSPECIFIED, sw-addrmethod=VAR_NO_INIT, symbol=VAR_NOINIT_UNSPECIFIED
        ComM_START_SEC_VAR_INIT_UNSPECIFIED: alignment=UNSPECIFIED, sw-addrmethod=VAR_INIT, symbol=VAR_INIT_UNSPECIFIED
        ComM_START_SEC_VAR_ZERO_INIT_UNSPECIFIED: alignment=UNSPECIFIED, sw-addrmethod=VAR_CLEARED, symbol=VAR_ZERO_INIT_UNSPECIFIED
